# STM32WLE5_CM4 register map
File version: 1.4
CPU: CM4 r0p1, little endian, MPU, FPU, 4 interrupt priority bits
Registers are 32-bit, read-write, reset 0x0 unless marked. A register's access mark holds for its fields unless they carry their own. Offsets are from the block's base; [hi:lo] are bit positions; {n}, {i} and the like mark numbered series.

## MPU — Memory protection unit
Base 0xE000ED90
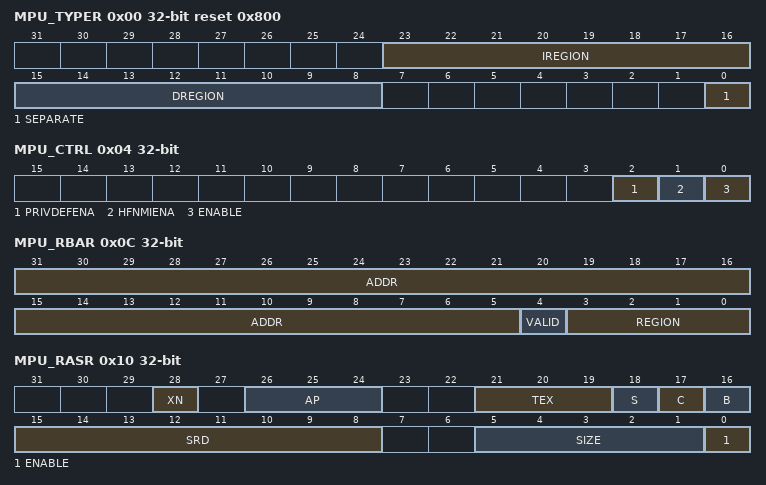
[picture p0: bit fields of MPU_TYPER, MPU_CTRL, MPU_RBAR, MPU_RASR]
0x00 MPU_TYPER ro reset 0x800 — MPU type register
  [23:16] IREGION — Number of MPU instruction regions
  [15:8] DREGION — Number of MPU data regions
  [0] SEPARATE — Separate flag
0x04 MPU_CTRL ro — MPU control register
  [2] PRIVDEFENA — Enable priviliged software access to default memory map
  [1] HFNMIENA — Enables the operation of MPU during hard fault
  [0] ENABLE — Enables the MPU
0x08 MPU_RNR — MPU region number register
  [7:0] REGION — MPU region
0x0C MPU_RBAR — MPU region base address register
  [31:5] ADDR — Region base address field
  [4] VALID — MPU region number valid
  [3:0] REGION — MPU region field
0x10 MPU_RASR — MPU region attribute and size register
  [28] XN — Instruction access disable bit
  [26:24] AP — Access permission
  [21:19] TEX — memory attribute
  [18] S — Shareable memory attribute
  [17] C — memory attribute
  [16] B — memory attribute
  [15:8] SRD — Subregion disable bits
  [5:1] SIZE — Size of the MPU protection region
  [0] ENABLE — Region enable bit.

## NVIC — Nested Vectored Interrupt Controller
Base 0xE000E100
0x00 ISER0 — Interrupt Set-Enable Register
  [31:0] SETENA
0x04 ISER1 — Interrupt Set-Enable Register
  [31:0] SETENA
0x80 ICER0 — Interrupt Clear-Enable Register
  [31:0] CLRENA
0x84 ICER1 — Interrupt Clear-Enable Register
  [31:0] CLRENA
0x100 ISPR0 — Interrupt Set-Pending Register
  [31:0] SETPEND
0x104 ISPR1 — Interrupt Set-Pending Register
  [31:0] SETPEND
0x180 ICPR0 — Interrupt Clear-Pending Register
  [31:0] CLRPEND
0x184 ICPR1 — Interrupt Clear-Pending Register
  [31:0] CLRPEND
0x200 IABR0 ro — Interrupt Active Bit Register
  [31:0] ACTIVE
0x204 IABR1 ro — Interrupt Active Bit Register
  [31:0] ACTIVE
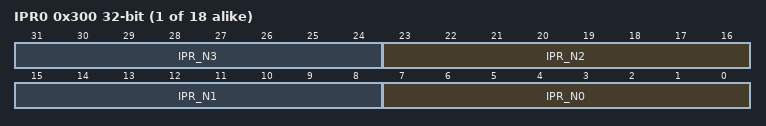
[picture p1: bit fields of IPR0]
{0x300+4i} IPR{i} (i=0..17) — Interrupt Priority Register
  [8n+7:8n] IPR_N{n} (n=0..3)

## NVIC_STIR — Nested vectored interrupt controller
Base 0xE000EF00
0x00 STIR — Software trigger interrupt register
  [8:0] INTID — Software generated interrupt ID

## PKA — Public key accelerator
Base 0x58002000
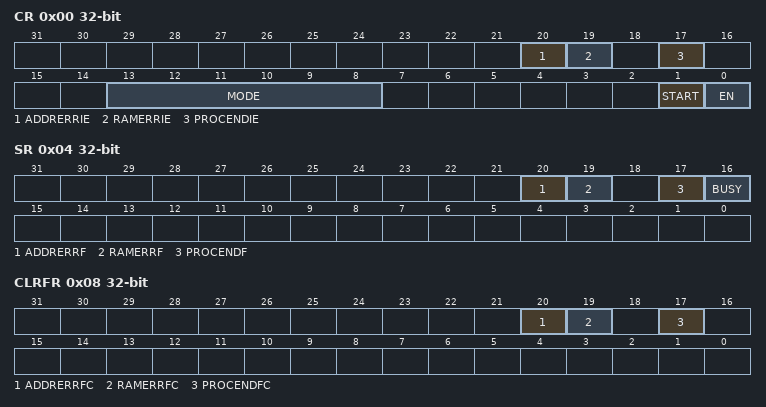
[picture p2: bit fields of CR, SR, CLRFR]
0x00 CR — control register
  [20] ADDRERRIE — Address error interrupt enable
  [19] RAMERRIE — RAM error interrupt enable
  [17] PROCENDIE
  [13:8] MODE — PKA operation code
  [1] START — start the operation
  [0] EN — PKA enable.
0x04 SR ro — status register
  [20] ADDRERRF — Address error flag
  [19] RAMERRF — PKA RAM error flag
  [17] PROCENDF — PKA End of Operation flag
  [16] BUSY — PKA operation is in progressThis bit is set to 1 whenever START bit in the PKA_CR is set. It is automatically cleared when the computation is complete, meaning that PKA RAM can be safely accessed and a new operation can be started.
0x08 CLRFR wo — clear flag register
  [20] ADDRERRFC — Clear Address error flag
  [19] RAMERRFC — Clear PKA RAM error flag
  [17] PROCENDFC — Clear PKA End of Operation flag

## RNG — True random number generator
Base 0x58001000
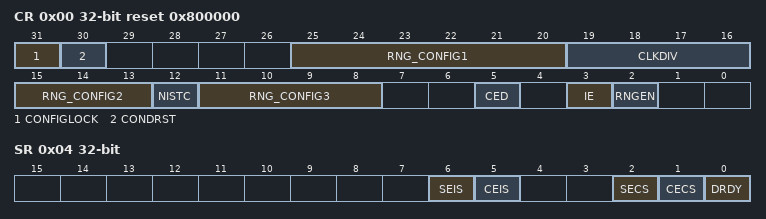
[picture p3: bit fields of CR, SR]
0x00 CR reset 0x800000 — control register
  [31] CONFIGLOCK
  [30] CONDRST — Conditioning soft reset
  [25:20] RNG_CONFIG1
  [19:16] CLKDIV
  [15:13] RNG_CONFIG2
  [12] NISTC
  [11:8] RNG_CONFIG3
  [5] CED — Interrupt Enable
  [3] IE — Interrupt Enable
  [2] RNGEN — True random number generator enable
0x04 SR access per field — status register
  [6] SEIS rw — Seed error interrupt status
  [5] CEIS rw — Clock error interrupt status
  [2] SECS ro — Seed error current status
  [1] CECS ro — Clock error current status
  [0] DRDY ro — Data Ready
0x08 DR ro — data register
  [31:0] RNDATA — Random data
0x10 HTCR reset 0x5A4E — health test control register
  [31:0] HTCFG — health test configuration
